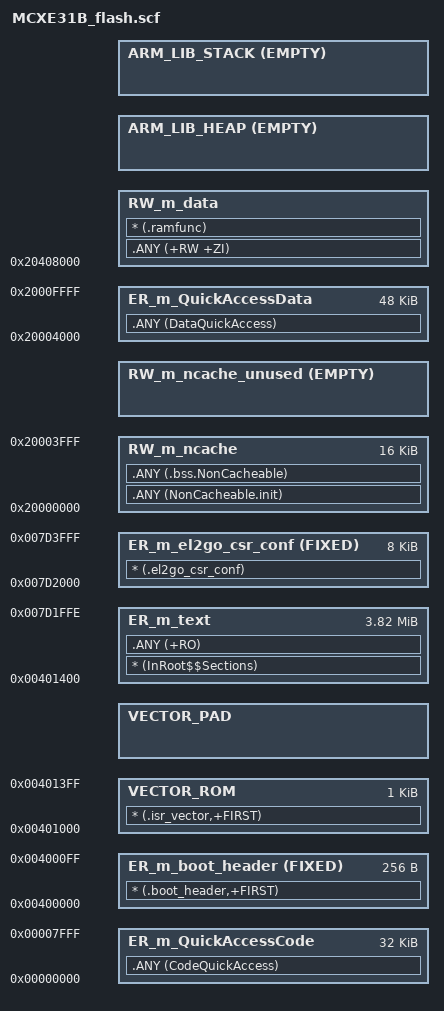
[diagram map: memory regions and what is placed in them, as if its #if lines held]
#!armclang --target=arm-arm-none-eabi -mcpu=cortex-m7 -E -x c

/*
** ###################################################################
**     Processor:           MCXE31BMPB_M7
**     Compiler:            Keil ARM C/C++ Compiler
**     Reference manual:    MCXE31 RM Rev2
**     Version:             rev. 1.1, 2025-11-07
**     Build:               b251107
**
**     Abstract:
**         Linker file for the Keil ARM C/C++ Compiler
**
**     Copyright 2016 Freescale Semiconductor, Inc.
**     Copyright 2016-2025 NXP
**     SPDX-License-Identifier: BSD-3-Clause
**
**     http:                 www.nxp.com
**     mail:                 support@nxp.com
**
** ###################################################################
*/

#define m_itcm_start                   0x00000000
#define m_itcm_end                     0x00007FFF

#define m_dtcm_start                   0x20000000
#define m_dtcm_end                     0x2000FFFF

#define m_stdby_ram_start              0x20400000
#define m_stdby_ram_end                0x20407FFF

#define m_interrupts_start             0x00401000
#define m_interrupts_size              0x00000400

#define m_boot_header_start            0x00400000
#define m_boot_header_size             0x00000100

#define m_text_start                   0x00401400
#define m_text_size                    0x003D0BFF

#define m_el2go_csr_conf_start         0x007D2000
#define m_el2go_csr_conf_size          0x00002000

#define m_data_start                   0x20408000
#define m_data_size                    0x00048000

#define m_ncache_size                  0x00004000
#define m_ncache_start                 m_dtcm_start
#define m_ncache_end                   m_ncache_start + m_ncache_size - 1

#define m_qacode_start                 m_itcm_start
#define m_qacode_end                   m_itcm_end
#define m_qadata_start                 m_ncache_end + 1
#define m_qadata_end                   m_dtcm_end

/* Sizes */
#if (defined(__stack_size__))
  #define Stack_Size                   __stack_size__
#else
  #define Stack_Size                   0x0400
#endif

#if (defined(__heap_size__))
  #define Heap_Size                    __heap_size__
#else
  #define Heap_Size                    0x0400
#endif

LR_m_header m_boot_header_start m_boot_header_size {
  ER_m_boot_header m_boot_header_start FIXED m_boot_header_size {
    * (.boot_header,+FIRST)
  }
}

LR_m_text m_interrupts_start m_interrupts_size+m_text_size {
  VECTOR_ROM m_interrupts_start m_interrupts_size {
    * (.isr_vector,+FIRST)
  }
  VECTOR_PAD +0 FILL 0x0 m_text_start-ImageLimit(VECTOR_ROM) {
  }
  ER_m_text m_text_start m_text_size {
    * (InRoot$$Sections)
    .ANY (+RO)
  }

  ER_m_QuickAccessCode m_qacode_start m_qacode_end-m_qacode_start+1 {
    .ANY (CodeQuickAccess)
  }

  ER_m_QuickAccessData m_qadata_start m_qadata_end-m_qadata_start+1 {
    .ANY (DataQuickAccess)
  }

  RW_m_ncache m_ncache_start m_ncache_size {
    .ANY (NonCacheable.init)
    .ANY (.bss.NonCacheable)
  }

  RW_m_ncache_unused +0 EMPTY m_ncache_size-ImageLength(RW_m_ncache) {
  }

  RW_m_data m_data_start m_data_size-Stack_Size-Heap_Size {
    .ANY (+RW +ZI)
    * (.ramfunc)
  }

  ARM_LIB_HEAP +0 EMPTY Heap_Size {
  }
  ARM_LIB_STACK m_data_start+m_data_size EMPTY -Stack_Size {
  }
}

LR_m_el2go_csr_conf m_el2go_csr_conf_start m_el2go_csr_conf_size {
  ER_m_el2go_csr_conf m_el2go_csr_conf_start FIXED m_el2go_csr_conf_size {
    * (.el2go_csr_conf)
  }
}
